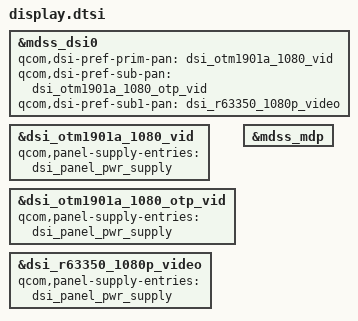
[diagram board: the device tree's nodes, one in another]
//Note: dsi_r69006_1080p_cmd is not for wt89536?
/* msm8953-panels-taco.dtsi */
#include "panels/dsi-panel-otm1901a-dj-1080p-video_otp.dtsi"
#include "panels/dsi-panel-otm1901a-dj-1080p-video.dtsi"
#include "panels/dsi-panel-r63350-tianma-1080p-video.dtsi"

/* msm8953-qrd-sku3.dtsi */
&mdss_dsi0 {
    /delete-property/ vdd-supply;
    qcom,dsi-pref-prim-pan = <&dsi_otm1901a_1080_vid>;
    qcom,dsi-pref-sub-pan = <&dsi_otm1901a_1080_otp_vid>;
    qcom,dsi-pref-sub1-pan = <&dsi_r63350_1080p_video>;
};

&dsi_otm1901a_1080_vid {
	qcom,panel-supply-entries = <&dsi_panel_pwr_supply>;
};

&dsi_otm1901a_1080_otp_vid {
	qcom,panel-supply-entries = <&dsi_panel_pwr_supply>;
};

&dsi_r63350_1080p_video {
	qcom,panel-supply-entries = <&dsi_panel_pwr_supply>;
};

&mdss_mdp {
	/delete-node/ qcom,mdss_dsi_sim_video;
	/delete-node/ qcom,mdss_dsi_dual_sim_video;
	/delete-node/ qcom,mdss_dsi_sim_cmd;
	/delete-node/ qcom,mdss_dsi_dual_sim_cmd;
	/delete-node/ qcom,mdss_dsi_truly_1080p_video;
	/delete-node/ qcom,mdss_dsi_truly_1080p_cmd;
	/delete-node/ qcom,mdss_dsi_adv7533_1080p;
	/delete-node/ qcom,mdss_dsi_adv7533_720p;
	/delete-node/ qcom,mdss_dsi_r69006_1080p_video;
	/delete-node/ qcom,mdss_dsi_r69006_1080p_cmd;
	/delete-node/ qcom,mdss_dsi_truly_wuxga_video;
	/delete-node/ qcom,mdss_dsi_lt8912_1080p_video;
	/delete-node/ qcom,mdss_dsi_lt8912_480p_video;
	/delete-node/ qcom,mdss_dsi_hx8399c_truly_video;
	/delete-node/ qcom,mdss_dsi_boyi_hx83100a_800p_video;
	/delete-node/ qcom,mdss_dsi_boent51021_1200p_video;
	/delete-node/ qcom,mdss_dsi_hx8394d_kingdisplay_vid;
	/delete-node/ qcom,mdss_dsi_inxnt51021_1200p_video;
};



